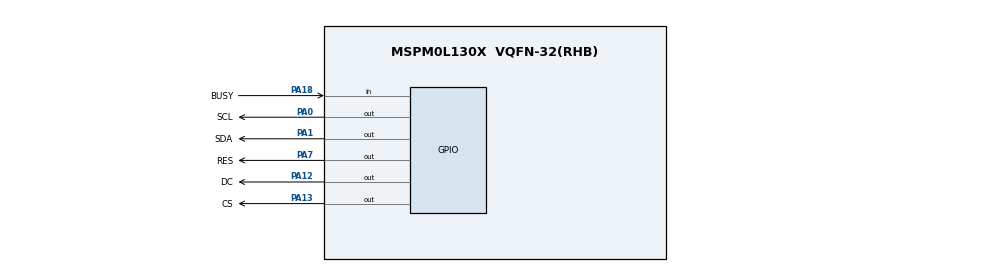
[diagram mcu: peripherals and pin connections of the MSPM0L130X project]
/**
 * @cliArgs --device "MSPM0L130X" --package "VQFN-32(RHB)" --part "Default" --product "mspm0_sdk@1.20.01.06"
 * @versions {"tool":"1.18.1+3343"}
 */

/**
 * Import the modules used in this configuration.
 */
const Board  = scripting.addModule("/ti/driverlib/Board");
const GPIO   = scripting.addModule("/ti/driverlib/GPIO", {}, false);
const GPIO1  = GPIO.addInstance();
const SYSCTL = scripting.addModule("/ti/driverlib/SYSCTL");

/**
 * Write custom configuration values to the imported modules.
 */
const gate6  = system.clockTree["MFCLKGATE"];
gate6.enable = true;

const gate7  = system.clockTree["MFPCLKGATE"];
gate7.enable = true;


GPIO1.$name                          = "GPIO_GRP_0";
GPIO1.associatedPins.create(6);
GPIO1.associatedPins[0].$name        = "SCL";
GPIO1.associatedPins[0].assignedPort = "PORTA";
GPIO1.associatedPins[0].pin.$assign  = "PA0";
GPIO1.associatedPins[1].$name        = "SDA";
GPIO1.associatedPins[1].pin.$assign  = "PA1";
GPIO1.associatedPins[2].$name        = "RES";
GPIO1.associatedPins[2].pin.$assign  = "PA7";
GPIO1.associatedPins[3].$name        = "DC";
GPIO1.associatedPins[3].pin.$assign  = "PA12";
GPIO1.associatedPins[4].$name        = "CS";
GPIO1.associatedPins[4].pin.$assign  = "PA13";
GPIO1.associatedPins[5].$name        = "BUSY";
GPIO1.associatedPins[5].direction    = "INPUT";
GPIO1.associatedPins[5].assignedPort = "PORTA";
GPIO1.associatedPins[5].pin.$assign  = "PA18";

SYSCTL.MFCLKEn     = true;
SYSCTL.MFPCLKEn    = true;
SYSCTL.clockTreeEn = true;

/**
 * Pinmux solution for unlocked pins/peripherals. This ensures that minor changes to the automatic solver in a future
 * version of the tool will not impact the pinmux you originally saw.  These lines can be completely deleted in order to
 * re-solve from scratch.
 */
Board.peripheral.$suggestSolution          = "DEBUGSS";
Board.peripheral.swclkPin.$suggestSolution = "PA20";
Board.peripheral.swdioPin.$suggestSolution = "PA19";
